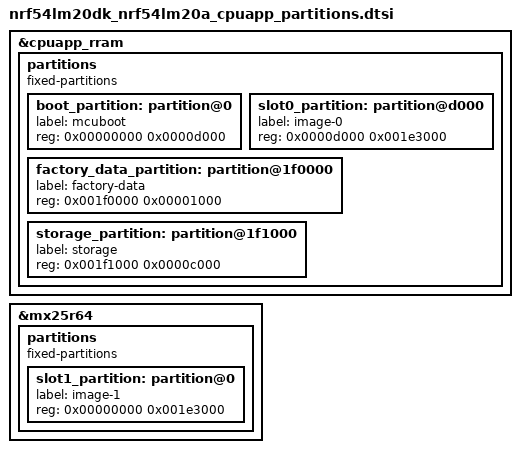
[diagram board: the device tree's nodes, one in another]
/*
 * Copyright (c) 2025 Nordic Semiconductor ASA
 *
 * SPDX-License-Identifier: LicenseRef-Nordic-5-Clause
 */

/delete-node/ &boot_partition;
/delete-node/ &slot0_partition;
/delete-node/ &slot1_partition;
/delete-node/ &storage_partition;

&cpuapp_rram {
	partitions {
		compatible = "fixed-partitions";
		#address-cells = <1>;
		#size-cells = <1>;

		boot_partition: partition@0 {
			label = "mcuboot";
			reg = <0x00000000 0x0000d000>;
		};

		slot0_partition: partition@d000 {
			label = "image-0";
			reg = <0x0000d000 0x001e3000>;
		};

		factory_data_partition: partition@1f0000 {
			label = "factory-data";
			reg = <0x001f0000 0x00001000>;
		};

		storage_partition: partition@1f1000 {
			label = "storage";
			reg = <0x001f1000 0x0000c000>;
		};
	};
};

&mx25r64 {
	status = "okay";

	partitions {
		compatible = "fixed-partitions";
		#address-cells = <1>;
		#size-cells = <1>;

		slot1_partition: partition@0 {
			label = "image-1";
			reg = <0x00000000 0x001e3000>;
		};
	};
};
